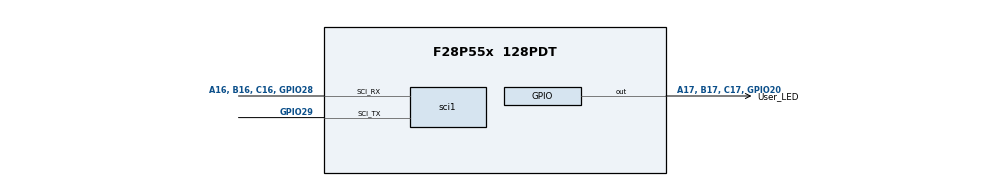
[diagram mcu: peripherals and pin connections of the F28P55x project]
/**
 * @cliArgs --device "F28P55x" --part "F28P55x_128PDT" --package "128PDT" --context "system" --product "C2000WARE@5.05.00.00"
 * @versions {"tool":"1.24.0+4110"}
 */

/**
 * Import the modules used in this configuration.
 */
const gpio  = scripting.addModule("/driverlib/gpio.js", {}, false);
const gpio1 = gpio.addInstance();
const sci   = scripting.addModule("/driverlib/sci.js", {}, false);
const sci1  = sci.addInstance();

/**
 * Write custom configuration values to the imported modules.
 */
gpio1.$name           = "User_LED";
gpio1.direction       = "GPIO_DIR_MODE_OUT";
gpio1.gpioPin.$assign = "A17, B17, C17, GPIO20";

sci1.useFifo                    = false;
sci1.$name                      = "User_UART";
sci1.selectRegisteredInterrupts = ["registerRxInt"];
sci1.enabledInterrupts          = ["SCI_INT_RXRDY_BRKDT"];
sci1.sci.sci_rxPin.$assign      = "A16, B16, C16, GPIO28";
sci1.sci.sci_txPin.$assign      = "GPIO29";
sci1.rxQual.$name               = "myGPIOQUAL0";
sci1.txQual.$name               = "myGPIOQUAL1";
sci1.sciRXInt.enableInterrupt   = true;

/**
 * Pinmux solution for unlocked pins/peripherals. This ensures that minor changes to the automatic solver in a future
 * version of the tool will not impact the pinmux you originally saw.  These lines can be completely deleted in order to
 * re-solve from scratch.
 */
sci1.sci.$suggestSolution = "SCIA";
